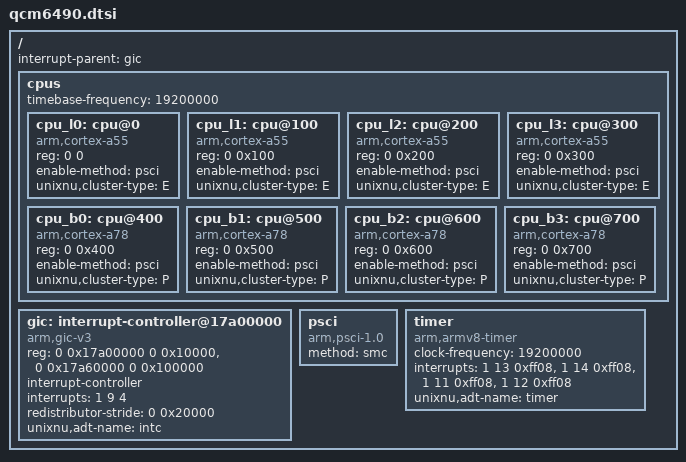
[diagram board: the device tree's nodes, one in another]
/*
 * QCM6490 resources used for the first UniXNU bring-up pass.
 * Hardware references: Fairphone 5 vendor_boot DTB 16 (VT32) and
 * Linux qcom/kodiak.dtsi. Values below are not a substitute for the live FP5 FDT.
 */

/ {
	#address-cells = <2>;
	#size-cells = <2>;
	interrupt-parent = <&gic>;

	cpus {
		#address-cells = <2>;
		#size-cells = <0>;
		timebase-frequency = <19200000>;

		cpu_l0: cpu@0 {
			device_type = "cpu";
			compatible = "arm,cortex-a55";
			reg = <0 0>;
			enable-method = "psci";
			unixnu,cluster-type = "E";
		};

		cpu_l1: cpu@100 {
			device_type = "cpu";
			compatible = "arm,cortex-a55";
			reg = <0 0x100>;
			enable-method = "psci";
			unixnu,cluster-type = "E";
		};

		cpu_l2: cpu@200 {
			device_type = "cpu";
			compatible = "arm,cortex-a55";
			reg = <0 0x200>;
			enable-method = "psci";
			unixnu,cluster-type = "E";
		};

		cpu_l3: cpu@300 {
			device_type = "cpu";
			compatible = "arm,cortex-a55";
			reg = <0 0x300>;
			enable-method = "psci";
			unixnu,cluster-type = "E";
		};

		cpu_b0: cpu@400 {
			device_type = "cpu";
			compatible = "arm,cortex-a78";
			reg = <0 0x400>;
			enable-method = "psci";
			unixnu,cluster-type = "P";
		};

		cpu_b1: cpu@500 {
			device_type = "cpu";
			compatible = "arm,cortex-a78";
			reg = <0 0x500>;
			enable-method = "psci";
			unixnu,cluster-type = "P";
		};

		cpu_b2: cpu@600 {
			device_type = "cpu";
			compatible = "arm,cortex-a78";
			reg = <0 0x600>;
			enable-method = "psci";
			unixnu,cluster-type = "P";
		};

		cpu_b3: cpu@700 {
			device_type = "cpu";
			compatible = "arm,cortex-a78";
			reg = <0 0x700>;
			enable-method = "psci";
			unixnu,cluster-type = "P";
		};
	};

	gic: interrupt-controller@17a00000 {
		compatible = "arm,gic-v3";
		reg = <0 0x17a00000 0 0x10000>,
		      <0 0x17a60000 0 0x100000>;
		#interrupt-cells = <3>;
		interrupt-controller;
		interrupts = <1 9 4>;
		redistributor-stride = <0 0x20000>;
		unixnu,adt-name = "intc";
	};

	psci {
		compatible = "arm,psci-1.0";
		method = "smc";
	};

	timer {
		compatible = "arm,armv8-timer";
		clock-frequency = <19200000>;
		interrupts = <1 13 0xff08>, <1 14 0xff08>,
			     <1 11 0xff08>, <1 12 0xff08>;
		unixnu,adt-name = "timer";
	};
};
